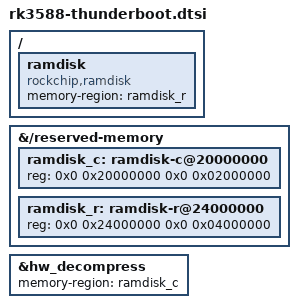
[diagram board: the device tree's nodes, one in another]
// SPDX-License-Identifier: (GPL-2.0+ OR MIT)
/*
 * Copyright (c) 2026 Rockchip Electronics Co., Ltd.
 */

/ {
	ramdisk: ramdisk {
		compatible = "rockchip,ramdisk";
		memory-region = <&ramdisk_r>;
	};
};

&{/reserved-memory} {
	ramdisk_c: ramdisk-c@20000000 {
		reg = <0x0 0x20000000 0x0 0x02000000>;
	};

	ramdisk_r: ramdisk-r@24000000 {
		reg = <0x0 0x24000000 0x0 0x04000000>;
	};
};

&hw_decompress {
	memory-region = <&ramdisk_c>;
	status = "okay";
};
